# ipro6s register map
Vendor: intelpro; Series: IPRO6S
CPU: ipro6s, little endian
Registers are 32-bit, read-write, reset 0x0 unless marked. A register's access mark holds for its fields unless they carry their own. Offsets are from the block's base; [hi:lo] are bit positions; {n}, {i} and the like mark numbered series.

## TZC_NSEC
Base 0x30007000
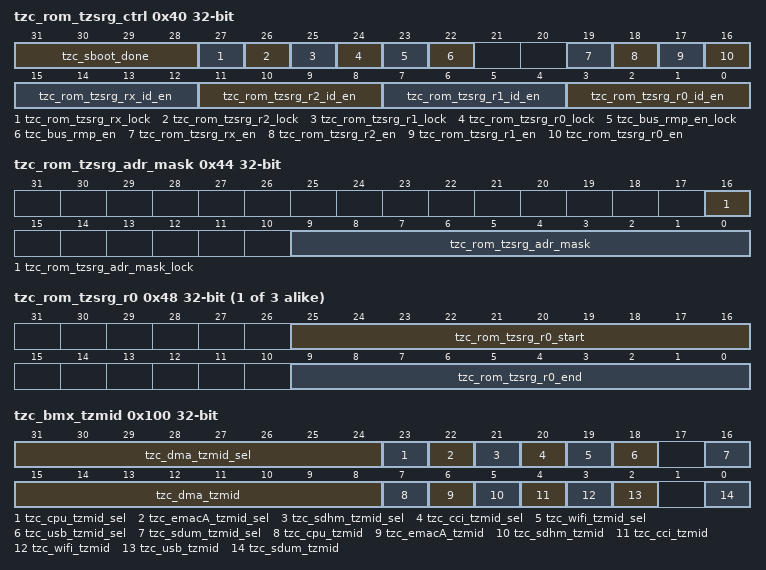
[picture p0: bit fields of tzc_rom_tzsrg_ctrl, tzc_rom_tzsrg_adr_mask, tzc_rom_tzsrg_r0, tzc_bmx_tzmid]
0x40 tzc_rom_tzsrg_ctrl reset not defined
  [31:28] tzc_sboot_done ro, [27] tzc_rom_tzsrg_rx_lock ro, [26] tzc_rom_tzsrg_r2_lock ro, [25] tzc_rom_tzsrg_r1_lock ro, [24] tzc_rom_tzsrg_r0_lock ro, [23] tzc_bus_rmp_en_lock ro, [22] tzc_bus_rmp_en ro, [19] tzc_rom_tzsrg_rx_en ro, [18] tzc_rom_tzsrg_r2_en ro, [17] tzc_rom_tzsrg_r1_en ro, [16] tzc_rom_tzsrg_r0_en ro, [15:12] tzc_rom_tzsrg_rx_id_en ro, [11:8] tzc_rom_tzsrg_r2_id_en ro, [7:4] tzc_rom_tzsrg_r1_id_en ro, [3:0] tzc_rom_tzsrg_r0_id_en ro
0x44 tzc_rom_tzsrg_adr_mask reset not defined
  [16] tzc_rom_tzsrg_adr_mask_lock ro — 1k byte align
  [9:0] tzc_rom_tzsrg_adr_mask ro — 1k byte align
{0x48+4i} tzc_rom_tzsrg_r{i} reset not defined (i=0..2)
  [25:16] tzc_rom_tzsrg_r{i}_start ro — 1k byte align
  [9:0] tzc_rom_tzsrg_r{i}_end ro — 1k byte align
0x54 tzc_rom_tzsrg_r3 reset not defined
0x100 tzc_bmx_tzmid reset not defined
  [31:24] tzc_dma_tzmid_sel ro, [23] tzc_cpu_tzmid_sel ro, [22] tzc_emacA_tzmid_sel ro, [21] tzc_sdhm_tzmid_sel ro, [20] tzc_cci_tzmid_sel ro, [19] tzc_wifi_tzmid_sel ro, [18] tzc_usb_tzmid_sel ro, [16] tzc_sdum_tzmid_sel ro, [15:8] tzc_dma_tzmid ro, [7] tzc_cpu_tzmid ro, [6] tzc_emacA_tzmid ro, [5] tzc_sdhm_tzmid ro, [4] tzc_cci_tzmid ro, [3] tzc_wifi_tzmid ro, [2] tzc_usb_tzmid ro, [0] tzc_sdum_tzmid ro
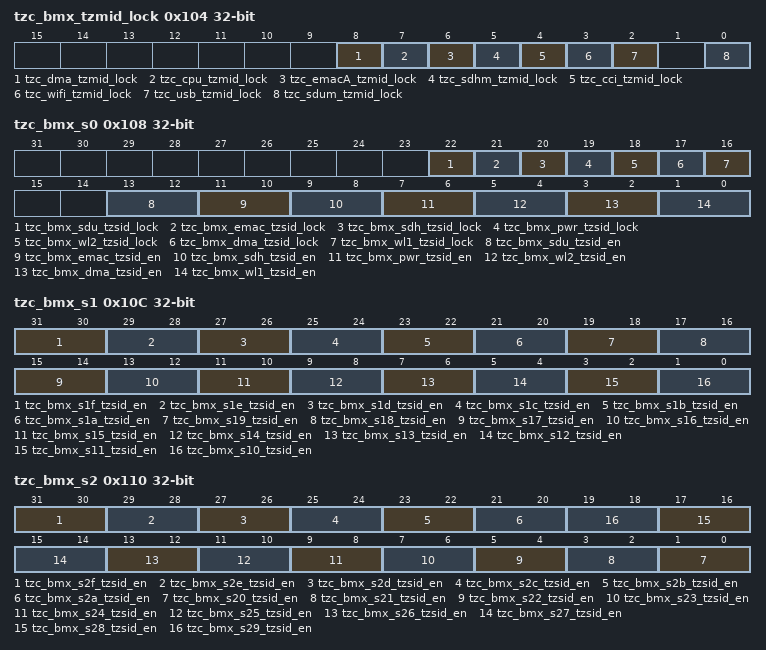
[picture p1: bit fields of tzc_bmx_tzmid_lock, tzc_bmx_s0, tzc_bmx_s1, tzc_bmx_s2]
0x104 tzc_bmx_tzmid_lock reset not defined
  [8] tzc_dma_tzmid_lock ro, [7] tzc_cpu_tzmid_lock ro, [6] tzc_emacA_tzmid_lock ro, [5] tzc_sdhm_tzmid_lock ro, [4] tzc_cci_tzmid_lock ro, [3] tzc_wifi_tzmid_lock ro, [2] tzc_usb_tzmid_lock ro, [0] tzc_sdum_tzmid_lock ro
0x108 tzc_bmx_s0 reset not defined
  [22] tzc_bmx_sdu_tzsid_lock ro — SDU (AHB)
  [21] tzc_bmx_emac_tzsid_lock ro — HBN/PDS (AHB)
  [20] tzc_bmx_sdh_tzsid_lock ro — DMA2 (AXI)
  [19] tzc_bmx_pwr_tzsid_lock ro — HBN/PDS (AHB)
  [18] tzc_bmx_wl2_tzsid_lock ro — WIFI (AHB)
  [17] tzc_bmx_dma_tzsid_lock ro — DMA (AHB)
  [16] tzc_bmx_wl1_tzsid_lock ro — BZ (AHB)
  [13:12] tzc_bmx_sdu_tzsid_en ro — SDU (AHB)
  [11:10] tzc_bmx_emac_tzsid_en ro — HBN/PDS (AHB)
  [9:8] tzc_bmx_sdh_tzsid_en ro — DMA2 (AXI)
  [7:6] tzc_bmx_pwr_tzsid_en ro — HBN/PDS (AHB)
  [5:4] tzc_bmx_wl2_tzsid_en ro — WIFI (AHB)
  [3:2] tzc_bmx_dma_tzsid_en ro — DMA (AHB)
  [1:0] tzc_bmx_wl1_tzsid_en ro — BZ (AHB)
0x10C tzc_bmx_s1 reset not defined
  [31:30] tzc_bmx_s1f_tzsid_en ro — I2C1
  [29:28] tzc_bmx_s1e_tzsid_en ro — I2C0
  [27:26] tzc_bmx_s1d_tzsid_en ro — SPI
  [25:24] tzc_bmx_s1c_tzsid_en ro — EFUSE
  [23:22] tzc_bmx_s1b_tzsid_en ro — UART1
  [21:20] tzc_bmx_s1a_tzsid_en ro — UART0
  [19:18] tzc_bmx_s19_tzsid_en ro — MCU_MISC
  [17:16] tzc_bmx_s18_tzsid_en ro — CCI
  [15:14] tzc_bmx_s17_tzsid_en ro — TZ2
  [13:12] tzc_bmx_s16_tzsid_en ro — TZ1
  [11:10] tzc_bmx_s15_tzsid_en ro — DBG
  [9:8] tzc_bmx_s14_tzsid_en ro — AGC
  [7:6] tzc_bmx_s13_tzsid_en ro — PHY
  [5:4] tzc_bmx_s12_tzsid_en ro — GPIP
  [3:2] tzc_bmx_s11_tzsid_en ro — RF
  [1:0] tzc_bmx_s10_tzsid_en ro — GLB
0x110 tzc_bmx_s2 reset not defined
  [31:30] tzc_bmx_s2f_tzsid_en ro — reserved
  [29:28] tzc_bmx_s2e_tzsid_en ro — reserved
  [27:26] tzc_bmx_s2d_tzsid_en ro — reserved
  [25:24] tzc_bmx_s2c_tzsid_en ro — reserved
  [23:22] tzc_bmx_s2b_tzsid_en ro — reserved
  [21:20] tzc_bmx_s2a_tzsid_en ro — reserved
  [2n-39:2n-40] tzc_bmx_s{n}_tzsid_en ro (n=20..29) — reserved
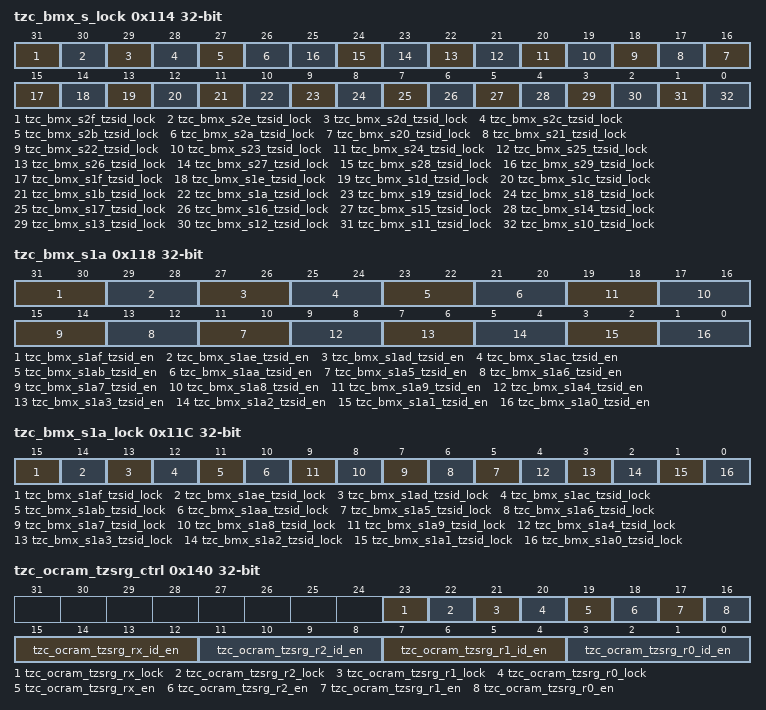
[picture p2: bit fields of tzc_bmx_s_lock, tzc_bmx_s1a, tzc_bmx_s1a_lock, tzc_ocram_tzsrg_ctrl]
0x114 tzc_bmx_s_lock reset not defined
  [31] tzc_bmx_s2f_tzsid_lock ro — reserved
  [30] tzc_bmx_s2e_tzsid_lock ro — reserved
  [29] tzc_bmx_s2d_tzsid_lock ro — reserved
  [28] tzc_bmx_s2c_tzsid_lock ro — reserved
  [27] tzc_bmx_s2b_tzsid_lock ro — reserved
  [26] tzc_bmx_s2a_tzsid_lock ro — reserved
  [n-4] tzc_bmx_s{n}_tzsid_lock ro (n=20..29) — reserved
  [15] tzc_bmx_s1f_tzsid_lock ro — I2C1
  [14] tzc_bmx_s1e_tzsid_lock ro — I2C0
  [13] tzc_bmx_s1d_tzsid_lock ro — SPI
  [12] tzc_bmx_s1c_tzsid_lock ro — EFUSE
  [11] tzc_bmx_s1b_tzsid_lock ro — UART1
  [10] tzc_bmx_s1a_tzsid_lock ro — UART0
  [9] tzc_bmx_s19_tzsid_lock ro — MCU_MISC
  [8] tzc_bmx_s18_tzsid_lock ro — CCI
  [7] tzc_bmx_s17_tzsid_lock ro — TZ2
  [6] tzc_bmx_s16_tzsid_lock ro — TZ1
  [5] tzc_bmx_s15_tzsid_lock ro — DBG
  [4] tzc_bmx_s14_tzsid_lock ro — AGC
  [3] tzc_bmx_s13_tzsid_lock ro — PHY
  [2] tzc_bmx_s12_tzsid_lock ro — GPIP
  [1] tzc_bmx_s11_tzsid_lock ro — RF
  [0] tzc_bmx_s10_tzsid_lock ro — GLB
0x118 tzc_bmx_s1a reset not defined
  [31:30] tzc_bmx_s1af_tzsid_en ro — reserved
  [29:28] tzc_bmx_s1ae_tzsid_en ro — reserved
  [27:26] tzc_bmx_s1ad_tzsid_en ro — reserved
  [25:24] tzc_bmx_s1ac_tzsid_en ro — reserved
  [23:22] tzc_bmx_s1ab_tzsid_en ro — reserved
  [21:20] tzc_bmx_s1aa_tzsid_en ro — reserved
  [2n+1:2n] tzc_bmx_s1a{n}_tzsid_en ro (n=5..9) — reserved
  [9:8] tzc_bmx_s1a4_tzsid_en ro — usb_phy
  [7:6] tzc_bmx_s1a3_tzsid_en ro — I2S
  [5:4] tzc_bmx_s1a2_tzsid_en ro — CKS
  [3:2] tzc_bmx_s1a1_tzsid_en ro — TMR
  [1:0] tzc_bmx_s1a0_tzsid_en ro — PWM
0x11C tzc_bmx_s1a_lock reset not defined
  [15] tzc_bmx_s1af_tzsid_lock ro — reserved
  [14] tzc_bmx_s1ae_tzsid_lock ro — reserved
  [13] tzc_bmx_s1ad_tzsid_lock ro — reserved
  [12] tzc_bmx_s1ac_tzsid_lock ro — reserved
  [11] tzc_bmx_s1ab_tzsid_lock ro — reserved
  [10] tzc_bmx_s1aa_tzsid_lock ro — reserved
  [n] tzc_bmx_s1a{n}_tzsid_lock ro (n=5..9) — reserved
  [4] tzc_bmx_s1a4_tzsid_lock ro — usb_phy
  [3] tzc_bmx_s1a3_tzsid_lock ro — I2S
  [2] tzc_bmx_s1a2_tzsid_lock ro — CKS
  [1] tzc_bmx_s1a1_tzsid_lock ro — TMR
  [0] tzc_bmx_s1a0_tzsid_lock ro — PWM
0x140 tzc_ocram_tzsrg_ctrl reset not defined
  [23] tzc_ocram_tzsrg_rx_lock ro
  [22] tzc_ocram_tzsrg_r2_lock ro
  [21] tzc_ocram_tzsrg_r1_lock ro
  [20] tzc_ocram_tzsrg_r0_lock ro
  [19] tzc_ocram_tzsrg_rx_en ro
  [18] tzc_ocram_tzsrg_r2_en ro
  [17] tzc_ocram_tzsrg_r1_en ro
  [16] tzc_ocram_tzsrg_r0_en ro
  [15:12] tzc_ocram_tzsrg_rx_id_en ro — tzsrg not in range r0~r2
  [11:8] tzc_ocram_tzsrg_r2_id_en ro — id_en[0]:id0 data id_en[1]:id0 instruction id_en[2]:id1 data id_en[3]:id1 instruction
  [7:4] tzc_ocram_tzsrg_r1_id_en ro — id_en[0]:id0 data id_en[1]:id0 instruction id_en[2]:id1 data id_en[3]:id1 instruction
  [3:0] tzc_ocram_tzsrg_r0_id_en ro — id_en[0]:id0 data id_en[1]:id0 instruction id_en[2]:id1 data id_en[3]:id1 instruction
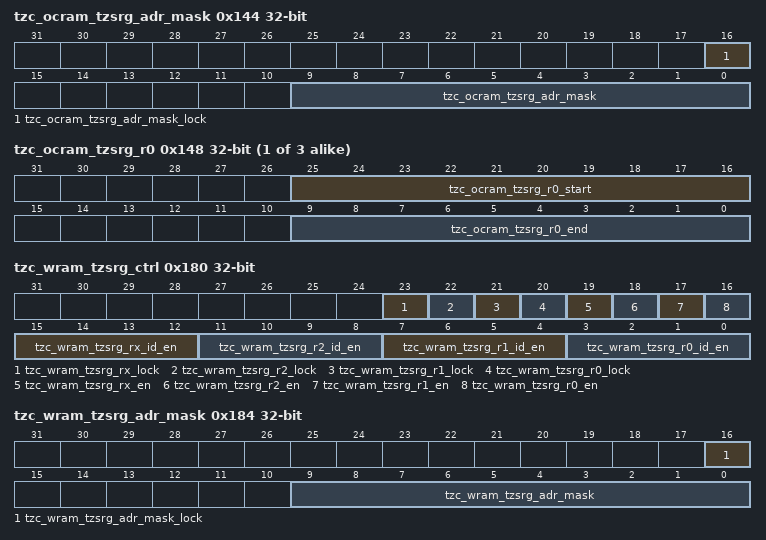
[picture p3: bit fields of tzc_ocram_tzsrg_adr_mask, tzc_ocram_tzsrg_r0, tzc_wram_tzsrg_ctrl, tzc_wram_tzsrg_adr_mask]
0x144 tzc_ocram_tzsrg_adr_mask reset not defined
  [16] tzc_ocram_tzsrg_adr_mask_lock ro — 1k byte align
  [9:0] tzc_ocram_tzsrg_adr_mask ro — 1k byte align
{0x148+4i} tzc_ocram_tzsrg_r{i} reset not defined (i=0..2)
  [25:16] tzc_ocram_tzsrg_r{i}_start ro — 1k byte align
  [9:0] tzc_ocram_tzsrg_r{i}_end ro — 1k byte align
0x154 tzc_ocram_tzsrg_r3 reset not defined
0x180 tzc_wram_tzsrg_ctrl reset not defined
  [23] tzc_wram_tzsrg_rx_lock ro
  [22] tzc_wram_tzsrg_r2_lock ro
  [21] tzc_wram_tzsrg_r1_lock ro
  [20] tzc_wram_tzsrg_r0_lock ro
  [19] tzc_wram_tzsrg_rx_en ro
  [18] tzc_wram_tzsrg_r2_en ro
  [17] tzc_wram_tzsrg_r1_en ro
  [16] tzc_wram_tzsrg_r0_en ro
  [15:12] tzc_wram_tzsrg_rx_id_en ro — tzsrg not in range r0~r2
  [11:8] tzc_wram_tzsrg_r2_id_en ro — id_en[0]:id0 data id_en[1]:id0 instruction id_en[2]:id1 data id_en[3]:id1 instruction
  [7:4] tzc_wram_tzsrg_r1_id_en ro — id_en[0]:id0 data id_en[1]:id0 instruction id_en[2]:id1 data id_en[3]:id1 instruction
  [3:0] tzc_wram_tzsrg_r0_id_en ro — id_en[0]:id0 data id_en[1]:id0 instruction id_en[2]:id1 data id_en[3]:id1 instruction
0x184 tzc_wram_tzsrg_adr_mask reset not defined
  [16] tzc_wram_tzsrg_adr_mask_lock ro — 1k byte align
  [9:0] tzc_wram_tzsrg_adr_mask ro — 1k byte align
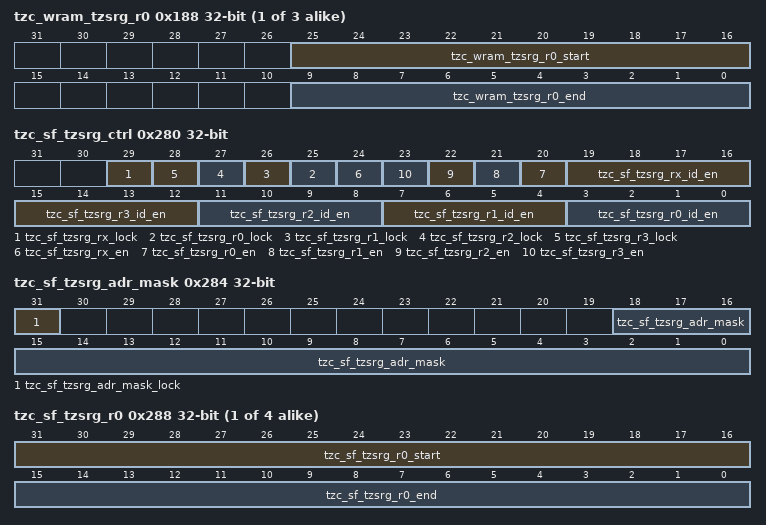
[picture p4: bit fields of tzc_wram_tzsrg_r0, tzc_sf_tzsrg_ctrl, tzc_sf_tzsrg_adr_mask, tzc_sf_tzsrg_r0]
{0x188+4i} tzc_wram_tzsrg_r{i} reset not defined (i=0..2)
  [25:16] tzc_wram_tzsrg_r{i}_start ro — 1k byte align
  [9:0] tzc_wram_tzsrg_r{i}_end ro — 1k byte align
0x194 tzc_wram_tzsrg_r3 reset not defined
0x198 tzc_wifi_dbg reset not defined
  [0] tzc_mac_dbg_dis ro — 1: disable wifi debug
0x240 tzc_pdm_ctrl reset not defined
0x244 tzc_uart_ctrl reset not defined
0x248 tzc_i2c_ctrl reset not defined
0x24C tzc_timer_ctrl reset not defined
0x250 tzc_i2s_ctrl reset not defined
0x280 tzc_sf_tzsrg_ctrl reset not defined
  [29] tzc_sf_tzsrg_rx_lock ro
  [n+25] tzc_sf_tzsrg_r{n}_lock ro (n=0..3)
  [24] tzc_sf_tzsrg_rx_en ro
  [n+20] tzc_sf_tzsrg_r{n}_en ro (n=0..3)
  [19:16] tzc_sf_tzsrg_rx_id_en ro — tzsrg not in range r0~r3
  [4n+3:4n] tzc_sf_tzsrg_r{n}_id_en ro (n=0..3) — id_en[0]:id0 instruction id_en[1]:id0 data id_en[2]:id1 instruction id_en[3]:id1 data
0x284 tzc_sf_tzsrg_adr_mask reset not defined
  [31] tzc_sf_tzsrg_adr_mask_lock ro — 1k byte align
  [18:0] tzc_sf_tzsrg_adr_mask ro — 1k byte align
{0x288+4i} tzc_sf_tzsrg_r{i} reset not defined (i=0..3)
  [31:16] tzc_sf_tzsrg_r{i}_start ro — 1k byte align
  [15:0] tzc_sf_tzsrg_r{i}_end ro — 1k byte align
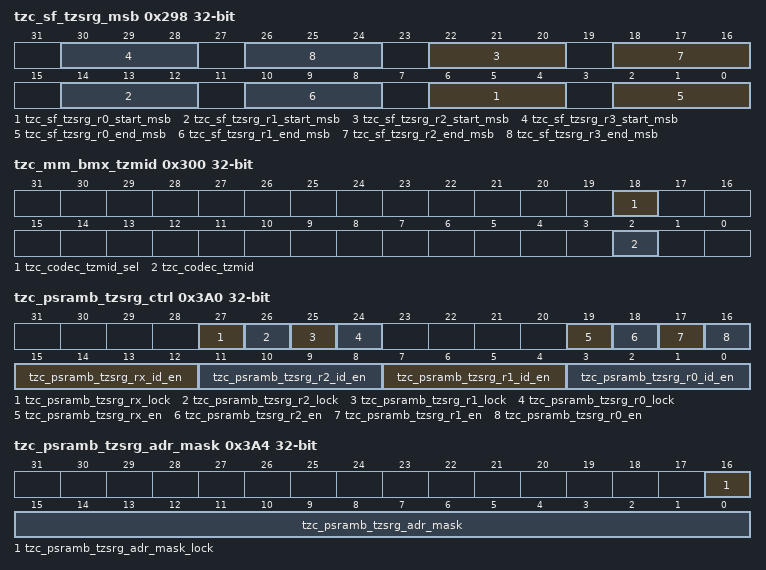
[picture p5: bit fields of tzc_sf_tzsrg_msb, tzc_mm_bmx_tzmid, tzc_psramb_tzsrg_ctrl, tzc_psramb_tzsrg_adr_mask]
0x298 tzc_sf_tzsrg_msb reset not defined
  [8n+6:8n+4] tzc_sf_tzsrg_r{n}_start_msb ro (n=0..3) — 1k byte align
  [8n+2:8n] tzc_sf_tzsrg_r{n}_end_msb ro (n=0..3) — 1k byte align
0x300 tzc_mm_bmx_tzmid reset not defined
  [18] tzc_codec_tzmid_sel ro, [2] tzc_codec_tzmid ro
0x304 tzc_mm_bmx_tzmid_lock reset not defined
  [2] tzc_codec_tzmid_lock ro
{0x308+4i} tzc_mm_bmx_s{i} reset not defined (i=0..2)
0x314 tzc_mm_bmx_s_lock0 reset not defined
0x318 tzc_mm_bmx_s_lock1 reset not defined
0x340 tzc_l2sram_tzsrg_ctrl reset not defined
0x344 tzc_l2sram_tzsrg_adr_mask reset not defined
{0x348+4i} tzc_l2sram_tzsrg_r{i} reset not defined (i=0..3)
0x360 tzc_vram_tzsrg_ctrl reset not defined
0x364 tzc_vram_tzsrg_adr_mask reset not defined
{0x368+4i} tzc_vram_tzsrg_r{i} reset not defined (i=0..3)
0x380 tzc_psrama_tzsrg_ctrl reset not defined
0x384 tzc_psrama_tzsrg_adr_mask reset not defined
{0x388+4i} tzc_psrama_tzsrg_r{i} reset not defined (i=0..3)
0x3A0 tzc_psramb_tzsrg_ctrl reset not defined
  [27] tzc_psramb_tzsrg_rx_lock ro, [26] tzc_psramb_tzsrg_r2_lock ro, [25] tzc_psramb_tzsrg_r1_lock ro, [24] tzc_psramb_tzsrg_r0_lock ro, [19] tzc_psramb_tzsrg_rx_en ro, [18] tzc_psramb_tzsrg_r2_en ro, [17] tzc_psramb_tzsrg_r1_en ro, [16] tzc_psramb_tzsrg_r0_en ro, [15:12] tzc_psramb_tzsrg_rx_id_en ro, [11:8] tzc_psramb_tzsrg_r2_id_en ro, [7:4] tzc_psramb_tzsrg_r1_id_en ro, [3:0] tzc_psramb_tzsrg_r0_id_en ro
0x3A4 tzc_psramb_tzsrg_adr_mask reset not defined
  [16] tzc_psramb_tzsrg_adr_mask_lock ro — 1k byte align
  [15:0] tzc_psramb_tzsrg_adr_mask ro — 1k byte align
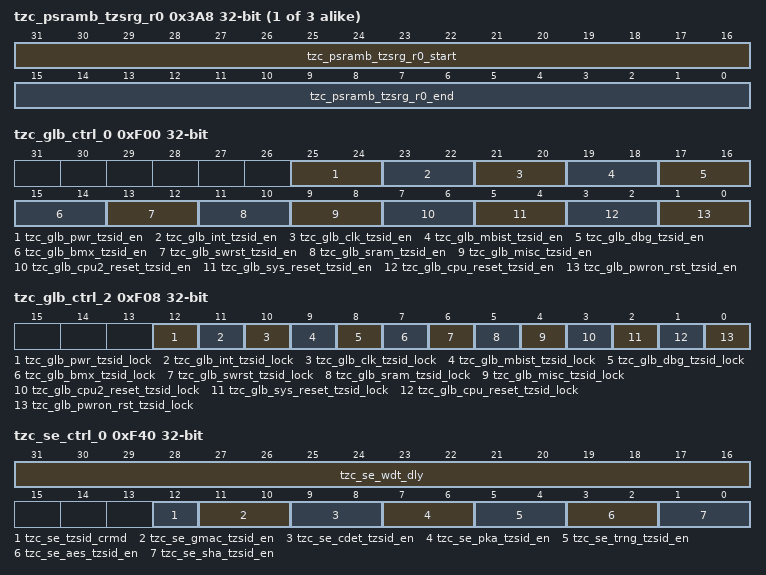
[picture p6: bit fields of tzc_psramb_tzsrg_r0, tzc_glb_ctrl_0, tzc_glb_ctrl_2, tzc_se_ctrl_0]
{0x3A8+4i} tzc_psramb_tzsrg_r{i} reset not defined (i=0..2)
  [31:16] tzc_psramb_tzsrg_r{i}_start ro — 1k byte align
  [15:0] tzc_psramb_tzsrg_r{i}_end ro — 1k byte align
0x3B4 tzc_psramb_tzsrg_r3 reset not defined
0x3C0 tzc_xram_tzsrg_ctrl reset not defined
0x3C4 tzc_xram_tzsrg_adr_mask reset not defined
{0x3C8+4i} tzc_xram_tzsrg_r{i} reset not defined (i=0..3)
0xF00 tzc_glb_ctrl_0 reset not defined
  [25:24] tzc_glb_pwr_tzsid_en ro
  [23:22] tzc_glb_int_tzsid_en ro
  [21:20] tzc_glb_clk_tzsid_en ro
  [19:18] tzc_glb_mbist_tzsid_en ro
  [17:16] tzc_glb_dbg_tzsid_en ro
  [15:14] tzc_glb_bmx_tzsid_en ro
  [13:12] tzc_glb_swrst_tzsid_en ro
  [11:10] tzc_glb_sram_tzsid_en ro
  [9:8] tzc_glb_misc_tzsid_en ro
  [7:6] tzc_glb_cpu2_reset_tzsid_en ro — reserved
  [5:4] tzc_glb_sys_reset_tzsid_en ro
  [3:2] tzc_glb_cpu_reset_tzsid_en ro — cpu
  [1:0] tzc_glb_pwron_rst_tzsid_en ro
0xF04 tzc_glb_ctrl_1 reset not defined
0xF08 tzc_glb_ctrl_2 reset not defined
  [12] tzc_glb_pwr_tzsid_lock ro
  [11] tzc_glb_int_tzsid_lock ro
  [10] tzc_glb_clk_tzsid_lock ro
  [9] tzc_glb_mbist_tzsid_lock ro
  [8] tzc_glb_dbg_tzsid_lock ro
  [7] tzc_glb_bmx_tzsid_lock ro
  [6] tzc_glb_swrst_tzsid_lock ro
  [5] tzc_glb_sram_tzsid_lock ro
  [4] tzc_glb_misc_tzsid_lock ro
  [3] tzc_glb_cpu2_reset_tzsid_lock ro — reserved
  [2] tzc_glb_sys_reset_tzsid_lock ro
  [1] tzc_glb_cpu_reset_tzsid_lock ro — cpu
  [0] tzc_glb_pwron_rst_tzsid_lock ro
{0xF20+4i} tzc_mm_ctrl_{i} reset not defined (i=0..2)
0xF40 tzc_se_ctrl_0 reset not defined
  [31:16] tzc_se_wdt_dly ro
  [12] tzc_se_tzsid_crmd ro — tzsid control register mode 0:arbiter mode 1:tzc control mode
  [11:10] tzc_se_gmac_tzsid_en ro
  [9:8] tzc_se_cdet_tzsid_en ro
  [7:6] tzc_se_pka_tzsid_en ro
  [5:4] tzc_se_trng_tzsid_en ro
  [3:2] tzc_se_aes_tzsid_en ro
  [1:0] tzc_se_sha_tzsid_en ro
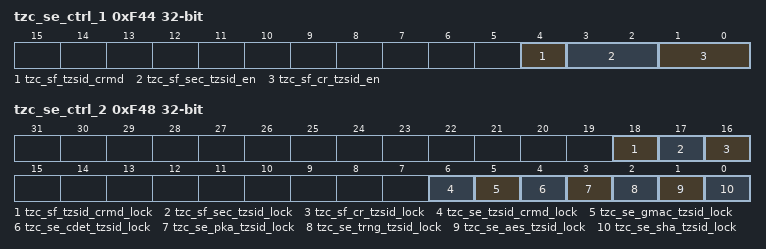
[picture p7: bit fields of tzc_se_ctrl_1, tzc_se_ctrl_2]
0xF44 tzc_se_ctrl_1 reset not defined
  [4] tzc_sf_tzsid_crmd ro — tzsid control register mode 0:arbiter mode 1:tzc control mode
  [3:2] tzc_sf_sec_tzsid_en ro — security registers tzsid enable
  [1:0] tzc_sf_cr_tzsid_en ro — control registers tzsid enable
0xF48 tzc_se_ctrl_2 reset not defined
  [18] tzc_sf_tzsid_crmd_lock ro, [17] tzc_sf_sec_tzsid_lock ro, [16] tzc_sf_cr_tzsid_lock ro, [6] tzc_se_tzsid_crmd_lock ro, [5] tzc_se_gmac_tzsid_lock ro, [4] tzc_se_cdet_tzsid_lock ro, [3] tzc_se_pka_tzsid_lock ro, [2] tzc_se_trng_tzsid_lock ro, [1] tzc_se_aes_tzsid_lock ro, [0] tzc_se_sha_tzsid_lock ro
